# MB9BF61xT register map
File version: 1.8
CPU: 
Registers are 32-bit, read-write, reset 0x0 unless marked. A register's access mark holds for its fields unless they carry their own. Offsets are from the block's base; [hi:lo] are bit positions; {n}, {i} and the like mark numbered series.

## WC — Watch Counter
Base 0x4003A000
0x00 WCRD 8-bit ro — Watch Counter Read Register
  [5:0] CTR — counter value
0x01 WCRL 8-bit — Watch Counter Reload Register
  [5:0] RLC — reload value
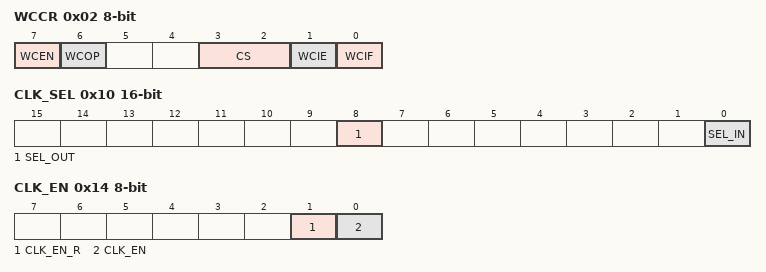
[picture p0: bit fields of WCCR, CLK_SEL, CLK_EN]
0x02 WCCR 8-bit — Watch Counter Control Register
  [7] WCEN — Watch counter operation enable bit
  [6] WCOP ro — Watch counter operating state flag
  [3:2] CS — Count clock select bits
  [1] WCIE — Interrupt request enable bit
  [0] WCIF — Interrupt request flag bit
0x10 CLK_SEL 16-bit — Clock Selection Register
  [8] SEL_OUT — Output clock selection bit
  [0] SEL_IN — Input clock selection bit
0x14 CLK_EN 8-bit — Division Clock Enable Register
  [1] CLK_EN_R — Division clock enable read bit
  [0] CLK_EN — Division clock enable bit

## EXTI — External Interrupt and NMI Control
Base 0x40030000
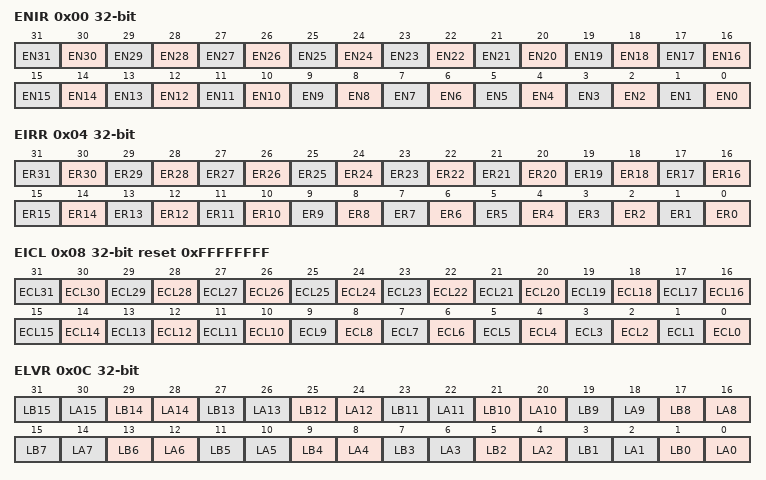
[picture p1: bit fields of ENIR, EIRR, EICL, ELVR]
0x00 ENIR — Enable Interrupt Request Register
  [n] EN{n} (n=0..31) — Bit{n} of ENIR
0x04 EIRR ro reset not defined — External Interrupt Request Register
  [n] ER{n} (n=0..31) — Bit{n} of EIRR
0x08 EICL reset 0xFFFFFFFF — External Interrupt Clear Register
  [n] ECL{n} (n=0..31) — Bit{n} of EICL
0x0C ELVR — External Interrupt Level Register
  [2n+1] LB{n} (n=0..15) — Bit{2n+1} of ELVR
  [2n] LA{n} (n=0..15) — Bit{2n} of ELVR
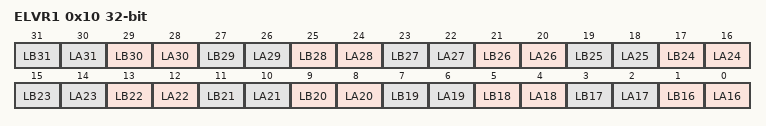
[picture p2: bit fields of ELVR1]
0x10 ELVR1 — External Interrupt Level Register 1
  [2n-31] LB{n} (n=16..31) — Bit{2n-31} of ELVR1
  [2n-32] LA{n} (n=16..31) — Bit{2n-32} of ELVR1
0x14 NMIRR 8-bit ro — Non Maskable Interrupt Request Register
  [0] NR — NMI interrupt request detection bit
0x18 NMICL 8-bit reset 0x1 — Non Maskable Interrupt Clear Register
  [0] NCL — NMI interrupt cause clear bit

## LVD — Low-voltage Detection
Base 0x40035000
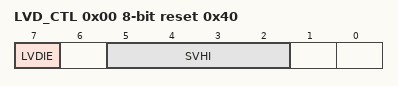
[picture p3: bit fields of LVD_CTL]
0x00 LVD_CTL 8-bit reset 0x40 — Low-voltage Detection Voltage Control Register
  [7] LVDIE — Low-voltage detection interrupt enable bit
  [5:2] SVHI — Low-voltage detection interrupt voltage setting bits
0x04 LVD_STR 8-bit ro — Low-voltage Detection Interrupt Register
  [7] LVDIR — Low-voltage detection interrupt bit
0x08 LVD_CLR 8-bit reset 0x80 — Low-voltage Detection Interrupt Clear Register
  [7] LVDCL — Low-voltage detection interrupt clear bit
0x0C LVD_RLR reset 0x1 — Low-voltage Detection Voltage Protection Register
  [31:0] LVDLCK — Low-voltage Detection Voltage Control Register protection bits
0x10 LVD_STR2 8-bit ro reset 0x40 — Low-voltage Detection Circuit Status Register
  [7] LVDIRDY — Low-voltage detection interrupt status flag

## MFS_NFC — I2C Auxiliary Noise Filter Setting Register
Base 0x40038800
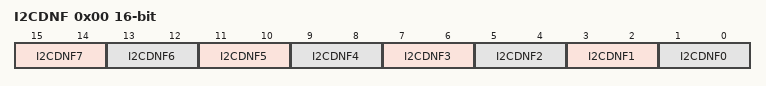
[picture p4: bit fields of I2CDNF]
0x00 I2CDNF 16-bit — I2C Auxiliary Noise Filter Setting Register
  [15:14] I2CDNF7 — Auxiliary noise filter additional step select bits for I2C ch.7
  [13:12] I2CDNF6 — Auxiliary noise filter additional step select bits for I2C ch.6
  [11:10] I2CDNF5 — Auxiliary noise filter additional step select bits for I2C ch.5
  [9:8] I2CDNF4 — Auxiliary noise filter additional step select bits for I2C ch.4
  [7:6] I2CDNF3 — Auxiliary noise filter additional step select bits for I2C ch.3
  [5:4] I2CDNF2 — Auxiliary noise filter additional step select bits for I2C ch.2
  [3:2] I2CDNF1 — Auxiliary noise filter additional step select bits for I2C ch.1
  [1:0] I2CDNF0 — Auxiliary noise filter additional step select bits for I2C ch.0

## CRC — CRC Registers
Base 0x40039000
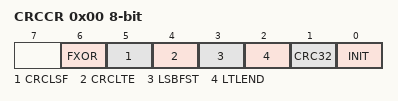
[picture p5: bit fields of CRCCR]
0x00 CRCCR 8-bit — CRC Control Register
  [6] FXOR — Initialization bit
  [5] CRCLSF — Final XOR control bit
  [4] CRCLTE — CRC result bit-order setting bit
  [3] LSBFST — CRC result byte-order setting bit
  [2] LTLEND — Bit-order setting bit
  [1] CRC32 — Byte-order setting bit
  [0] INIT — CRC mode selection bit
0x04 CRCINIT reset 0xFFFFFFFF — Initial Value Register
  [31:0] D — Initial value
0x08 CRCIN — Input Data Register
  [31:0] D — Input data
0x0C CRCR ro reset 0xFFFFFFFF — CRC Register
  [31:0] D — CRC Data
